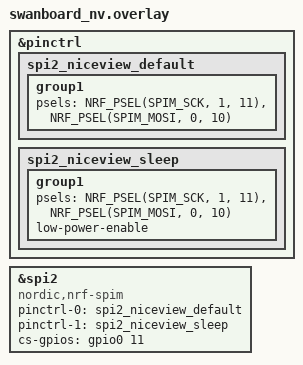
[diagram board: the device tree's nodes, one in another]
// swanboard_nv - nice!view on its own SPI bus (the ZMK nice_view shield needs "nice_view_spi").
// Use it together with the nice_view shield:  shield: swanboard swanboard_nv nice_view
//   CS   = P0.11   SCK = P1.11   MOSI = P0.10   (MISO not used)
//   VCC -> nice!nano VCC pin, GND -> GND
// P0.10 is an NFC pin: CONFIG_NFCT_PINS_AS_GPIOS=y (set in swanboard.conf).
// These pins are also used by the LEDs (swanboard_led): do not use both.

#include <zephyr/dt-bindings/pinctrl/nrf-pinctrl.h>

&pinctrl {
    spi2_niceview_default: spi2_niceview_default {
        group1 {
            psels = <NRF_PSEL(SPIM_SCK, 1, 11)>,
                    <NRF_PSEL(SPIM_MOSI, 0, 10)>;
        };
    };

    spi2_niceview_sleep: spi2_niceview_sleep {
        group1 {
            psels = <NRF_PSEL(SPIM_SCK, 1, 11)>,
                    <NRF_PSEL(SPIM_MOSI, 0, 10)>;
            low-power-enable;
        };
    };
};

nice_view_spi: &spi2 {
    compatible = "nordic,nrf-spim";
    status = "okay";
    pinctrl-0 = <&spi2_niceview_default>;
    pinctrl-1 = <&spi2_niceview_sleep>;
    pinctrl-names = "default", "sleep";
    cs-gpios = <&gpio0 11 GPIO_ACTIVE_HIGH>;
};
